# PIC32CM3204JH00064 register map
Vendor: Microchip Technology; Series: PIC32CMJH00; File version: 0
Microchip PIC32CM3204JH00064 Microcontroller
CPU: CM0+ r0p0, little endian, MPU, no FPU, VTOR, 2 interrupt priority bits, 31 interrupts
Registers are 32-bit, read-write, reset 0x0 unless marked. A register's access mark holds for its fields unless they carry their own. Offsets are from the block's base; lines under a group give offsets from that group; [hi:lo] are bit positions; {n}, {i} and the like mark numbered series; 'fields as' and 'values as' point back to an identical list; <NAME> marks a mode.

## Memory map
0x40000000 PAC size 0x40 — Peripheral Access Controller
0x40000400 PM size 0xA — Power Manager
0x40000800 MCLK size 0x20 — Main Clock
0x40000C00 RSTC size 0x1 — Reset Controller
0x40001000 OSCCTRL size 0x3C — Oscillators Control
0x40001400 OSC32KCTRL size 0x20 — 32k Oscillators Control
0x40001800 SUPC size 0x20 — Supply Controller
0x40001C00 GCLK size 0x124 — Generic Clock Generator
0x40002000 WDT size 0xD — Watchdog Timer
0x40002400 RTC size 0x25 — Real-Time Counter
0x40002800 EIC size 0x24 — External Interrupt Controller
0x40002C00 FREQM size 0x14 — Frequency Meter
0x41000000 PORT size 0x100 — Port Module
0x41002000 DSU size 0x2000 — Device Service Unit
0x41004000 NVMCTRL size 0x30 — Non-Volatile Memory Controller
0x41006000 DMAC size 0x50 — Direct Memory Access Controller
0x41008000 MTB size 0x1000 — Cortex-M0+ Micro-Trace Buffer
0x4100A000 HMATRIXHS size 0x150 — HSB Matrix
0x42000000 EVSYS size 0x13C — Event System Interface
0x42000400 SERCOM0 size 0x31 — Serial Communication Interface
0x42000800 SERCOM1 size 0x31
0x42000C00 SERCOM2 size 0x31
0x42001000 SERCOM3 size 0x31
0x42002400 TCC0 size 0x80 — Timer Counter Control
0x42002800 TCC1 size 0x80
0x42002C00 TCC2 size 0x80
0x42003000 TC0 size 0x38 — Basic Timer Counter
0x42003400 TC1 size 0x38
0x42003800 TC2 size 0x38
0x42003C00 TC3 size 0x38
0x42004000 TC4 size 0x38
0x42004400 ADC0 size 0x2E — Analog Digital Converter
0x42005000 AC size 0x24 — Analog Comparators
0x42005C00 CCL size 0x18 — Configurable Custom Logic
0x48000000 DIVAS size 0x1C — Divide and Square Root Accelerator
0x60000000 PORT_IOBUS size 0x100
0xE000E000 SystemControl size 0xD34 — System Control Registers
0xE000E010 SysTick size 0x10 — System timer
0xE000E100 NVIC size 0x320 — Nested Vectored Interrupt Controller
0xE000ED90 MPU size 0x14 — Memory Protection Unit

## Interrupts
0 SYSTEM (MCLK, OSCCTRL, OSC32KCTRL, PAC, SUPC) — System peripherals shared interrupt
1 WDT — Watchdog Timer
2 RTC — Real Time Counter
3 EIC — External Interrupt Controller
4 FREQM — Frequency Meter
6 NVMCTRL — Non-Volatile Memory Controller
7 DMAC — Direct Memory Controller
8 EVSYS — Event Systems
9 SERCOM0 — Serial Communication Interface 0
10 SERCOM1 — Serial Communication Interface 1
11 SERCOM2 — Serial Communication Interface 2
12 SERCOM3 — Serial Communication Interface 3
17 TCC0 — Timer/Counter for Control Applications 0
18 TCC1 — Timer/Counter for Control Applications 1
19 TCC2 — Timer/Counter for Control Applications 2
20 TC0 — Timer/Counter 0
21 TC1 — Timer/Counter 1
22 TC2 — Timer/Counter 2
23 TC3 — Timer/Counter 3
24 TC4 — Timer/Counter 4
25 ADC0 — Analog-to-Digital Converter 0
27 AC — Analog Comparators

## AC — Analog Comparators
Base 0x42005000
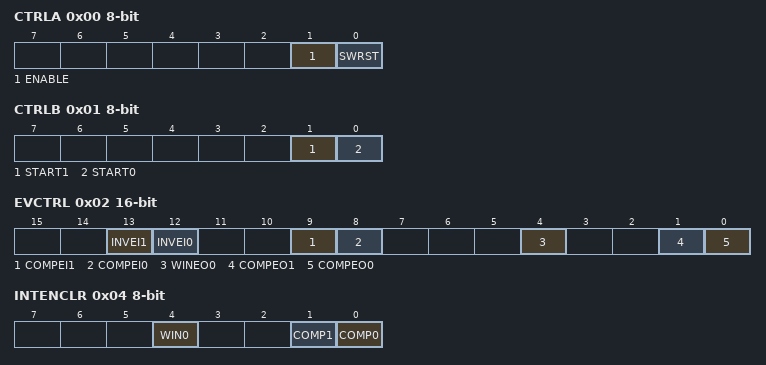
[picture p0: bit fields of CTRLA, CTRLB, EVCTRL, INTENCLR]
0x00 CTRLA 8-bit — Control A
  [1] ENABLE
  [0] SWRST — Software Reset
0x01 CTRLB 8-bit wo — Control B
  [1] START1 — Comparator 1 Start Comparison
  [0] START0 — Comparator 0 Start Comparison
0x02 EVCTRL 16-bit — Event Control
  [13] INVEI1 — Comparator 1 Input Event Invert Enable
  [12] INVEI0 — Comparator 0 Input Event Invert Enable
  [9] COMPEI1 — Comparator 1 Event Input Enable
  [8] COMPEI0 — Comparator 0 Event Input Enable
  [4] WINEO0 — Window 0 Event Output Enable
  [1] COMPEO1 — Comparator 1 Event Output Enable
  [0] COMPEO0 — Comparator 0 Event Output Enable
0x04 INTENCLR 8-bit write-1-clears — Interrupt Enable Clear
  [4] WIN0 — Window 0 Interrupt Enable
  [1] COMP1 — Comparator 1 Interrupt Enable
  [0] COMP0 — Comparator 0 Interrupt Enable
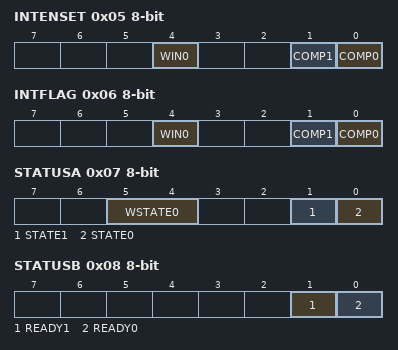
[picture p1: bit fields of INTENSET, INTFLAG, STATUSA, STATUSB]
0x05 INTENSET 8-bit write-1-sets — Interrupt Enable Set
  fields as INTENCLR
0x06 INTFLAG 8-bit write-1-clears — Interrupt Flag Status and Clear
  [4] WIN0 — Window 0
  [1] COMP1 — Comparator 1
  [0] COMP0 — Comparator 0
0x07 STATUSA 8-bit ro
  [5:4] WSTATE0 — Window 0 Current State
    0=ABOVE (Signal is above window); 1=INSIDE (Signal is inside window); 2=BELOW (Signal is below window)
  [1] STATE1 — Comparator 1 Current State
  [0] STATE0 — Comparator 0 Current State
0x08 STATUSB 8-bit ro
  [1] READY1 — Comparator 1 Ready
  [0] READY0 — Comparator 0 Ready
0x09 DBGCTRL 8-bit — Debug Control
  [0] DBGRUN — Debug Run
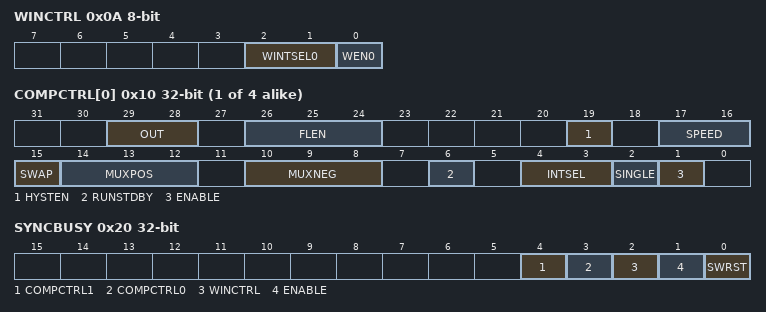
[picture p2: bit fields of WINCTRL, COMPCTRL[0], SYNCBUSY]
0x0A WINCTRL 8-bit — Window Control
  [2:1] WINTSEL0 — Window 0 Interrupt Selection
    0=ABOVE (Interrupt on signal above window); 1=INSIDE (Interrupt on signal inside window); 2=BELOW (Interrupt on signal below window); 3=OUTSIDE (Interrupt on signal outside window)
  [0] WEN0 — Window 0 Mode Enable
{0xC+i} SCALER[{i}] (i=0..3) 8-bit — Scaler n
  [5:0] VALUE — Scaler Value
{0x10+4i} COMPCTRL[{i}] (i=0..3) — Comparator Control n
  [29:28] OUT — Output
    0=OFF (The output of COMPn is not routed to the COMPn I/O port); 1=ASYNC (The asynchronous output of COMPn is routed to the COMPn I/O port); 2=SYNC (The synchronous output (including filtering) of COMPn is routed to the COMPn I/O port)
  [26:24] FLEN — Filter Length
    0=OFF (No filtering); 1=MAJ3 (3-bit majority function (2 of 3)); 2=MAJ5 (5-bit majority function (3 of 5))
  [19] HYSTEN — Hysteresis Enable
  [17:16] SPEED — Speed Selection
    0=LOW (Low speed); 3=HIGH (High speed)
  [15] SWAP — Swap Inputs and Invert
  [14:12] MUXPOS — Positive Input Mux Selection
    {v}=PIN{v} (I/O pin {v}) (v=0..3); 4=VSCALE (VDD Scaler)
  [10:8] MUXNEG — Negative Input Mux Selection
    {v}=PIN{v} (I/O pin {v}) (v=0..3); 4=GND (Ground); 5=VSCALE (VDD scaler); 6=BANDGAP (Internal bandgap voltage)
  [6] RUNSTDBY — Run in Standby
  [4:3] INTSEL — Interrupt Selection
    0=TOGGLE (Interrupt on comparator output toggle); 1=RISING (Interrupt on comparator output rising); 2=FALLING (Interrupt on comparator output falling); 3=EOC (Interrupt on end of comparison (single-shot mode only))
  [2] SINGLE — Single-Shot Mode
  [1] ENABLE
0x20 SYNCBUSY ro — Synchronization Busy
  [4] COMPCTRL1 — COMPCTRL 1 Synchronization Busy
  [3] COMPCTRL0 — COMPCTRL 0 Synchronization Busy
  [2] WINCTRL — WINCTRL Synchronization Busy
  [1] ENABLE — Enable Synchronization Busy
  [0] SWRST — Software Reset Synchronization Busy

## Licence text in the file
Copyright (c) 2026 Microchip Technology Inc. SPDX-License-Identifier: Apache-2.0 Licensed under the Apache License, Version 2.0 (the "License"); you may not use this file except in compliance with the License. You may obtain a copy of the License at http://www.apache.org/licenses/LICENSE-2.0 Unless required by applicable law or agreed to in writing, software distributed under the License is distributed on an "AS IS" BASIS, WITHOUT WARRANTIES OR CONDITIONS OF ANY KIND, either express or implied. See the License for the specific language governing permissions and limitations under the License.
